# LPC865 register map
Vendor: nxp.com; File version: 1.0
CPU: CM0PLUS r0p0, little endian, no MPU, no FPU, VTOR, 2 interrupt priority bits
Registers are 32-bit, read-write, reset 0x0 unless marked. A register's access mark holds for its fields unless they carry their own. Offsets are from the block's base; [hi:lo] are bit positions; {n}, {i} and the like mark numbered series.

## I3C0 — I3C
Base 0x40060000
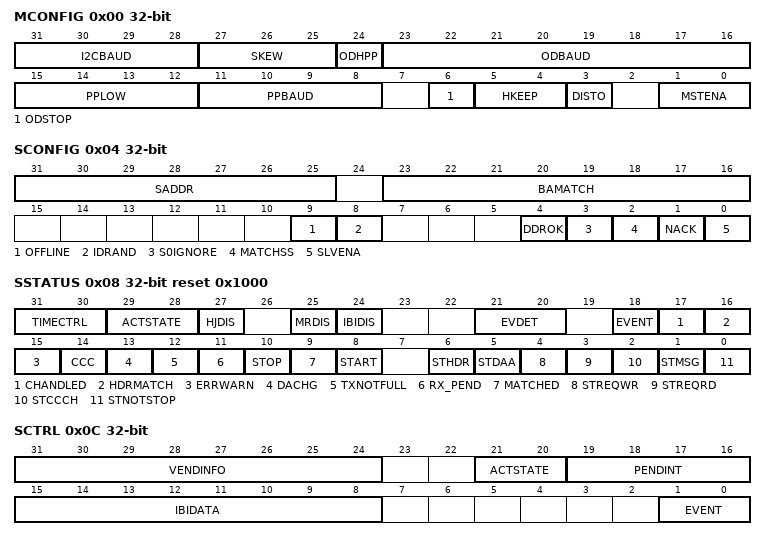
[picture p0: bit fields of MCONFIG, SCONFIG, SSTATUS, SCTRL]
0x00 MCONFIG — Master Configuration Register
  [31:28] I2CBAUD — I2C baud rate
  [27:25] SKEW
  [24] ODHPP — Open drain high push-pull
  [23:16] ODBAUD — Open drain baud rate
  [15:12] PPLOW — Push-Pull low
  [11:8] PPBAUD — Push-pull baud rate
  [6] ODSTOP — Open drain stop
  [5:4] HKEEP — High-Keeper
    0=NONE (NONE: Use PUR (Pull-Up Resistor). Hold SCL High.); 1=WIRED_IN (WIRED_IN: Wired-in High Keeper controls; use pin_HK (High Keeper) controls.); 2=PASSIVE_SDA (PASSIVE_SDA: Passive on SDA; can Hi-Z (high impedance) for Bus Free (IDLE) and hold.); 3=PASSIVE_ON_SDA_SCL (PASSIVE_ON_SDA_SCL: Passive on SDA and SCL; can Hi-Z (high impedance) both for Bus Free (IDLE), and can Hi-Z SDA for hold.)
  [3] DISTO — Disable Timeout
  [1:0] MSTENA — Master enable
    0=MASTER_OFF (MASTER_OFF: Master is off (is not enabled). If MASTER_OFF is enabled, then the I3C module can only use slave mode.); 1=MASTER_ON (MASTER_ON: Master is on (is enabled). When used from start-up, this I3C module is master by default (the main master). The module will control the bus unless the master is handed off. If the master is handed off, then MSTENA must move to 2 after that happens. The handoff means emitting GETACCMST and if accepted, the module will emit a STOP and set the MSTENA bit to 2 (or 0).); 2=MASTER_CAPABLE (MASTER_CAPABLE: The I3C module is master-capable; however the module is operating as a slave now. When used from the start, the I3C module will start as a slave, but will be prepared to switch to master mode. To switch to master mode, the slave emits an Master Request (MR), or gets a GETACCMST CCC command and accepts it (to switch on the STOP).)
0x04 SCONFIG — Slave Configuration Register
  [31:25] SADDR — Static address
  [23:16] BAMATCH — Bus available match
  [9] OFFLINE
  [8] IDRAND — ID random
  [4] DDROK — Double Data Rate OK
  [3] S0IGNORE — S0/S1 errors ignore
  [2] MATCHSS — Match START or STOP
  [1] NACK — Not acknowledge
  [0] SLVENA — Slave enable
0x08 SSTATUS reset 0x1000 (reset mask 0xFBC7FF7F) — Slave Status Register
  [31:30] TIMECTRL ro — Time control
    0=NO_TIME_CONTROL (NO_TIME_CONTROL: No time control is enabled); 2=ASYNC_MODE (ASYNC_MODE: Asynchronous standard mode (0) is enabled)
  [29:28] ACTSTATE ro — Activity state from Common Command Codes (CCC)
    0=NO_LATENCY (NO_LATENCY: normal bus operations); 1=LATENCY_1MS (LATENCY_1MS: 1 ms of latency); 2=LATENCY_100MS (LATENCY_100MS: 100 ms of latency); 3=LATENCY_10S (LATENCY_10S: 10 seconds of latency)
  [27] HJDIS ro — Hot-Join is disabled
  [25] MRDIS ro — Master requests are disabled
  [24] IBIDIS ro — In-Band Interrupts are disabled
  [21:20] EVDET ro — Event details
    0=NONE (NONE: no event or no pending event); 1=NO_REQUEST (NO_REQUEST: Request not sent yet. Either there was no START yet, or is waiting for Bus-Available or Bus-Idle (HJ).); 2=NACKED (NACKED: Not acknowledged(Request sent and NACKed); the module will try again.); 3=ACKED (ACKED: Acknowledged (Request sent and ACKed), so Done (unless the time control data is still being sent).)
  [18] EVENT
  [17] CHANDLED — Common-Command-Code handled
  [16] HDRMATCH — High Data Rate command match
  [15] ERRWARN ro — Error warning
  [14] CCC — Common Command Code
  [13] DACHG
  [12] TXNOTFULL ro — Transmit buffer is not full
  [11] RX_PEND ro — Received message pending
  [10] STOP
  [9] MATCHED
  [8] START
  [6] STHDR ro — Status High Data Rate
  [5] STDAA ro — Status Dynamic Address Assignment
  [4] STREQWR ro — Status request write
  [3] STREQRD ro — Status required
  [2] STCCCH ro — Status Common Command Code Handler
  [1] STMSG ro — Status message
  [0] STNOTSTOP ro — Status not stop
0x0C SCTRL — Slave Control Register
  [31:24] VENDINFO — Vendor information
  [21:20] ACTSTATE — Activity state (of slave)
  [19:16] PENDINT — Pending interrupt
  [15:8] IBIDATA — In-Band Interrupt data
  [1:0] EVENT
    0=NORMAL_MODE (NORMAL_MODE: If EVENT is set to 0 after was a non-0 value, event processing will cancel if the event processing has not yet started; if event processing has already been started, then event processing will not be be cancelled.); 1=IBI (IBI: Start an In-Band Interrupt. This will try to push an IBI interrupt onto the I3C bus. If data is associated with the IBI, then the data will be read from the SCTRL.IBIDATA field. If time control is enabled, then this data will also include any time control-related bytes; additionally, the IBIDATA byte will have bit 7 set to 1 automatically (as is required for time control). The IBI interrupt will occur after the 1st (mandatory) IBIDATA, if any.); 2=MASTER_REQUEST (MASTER_REQUEST: Start a Master-Request.); 3=HOT_JOIN_REQUEST (HOT_JOIN_REQUEST: Start a Hot-Join request. A Hot-Join Request should only be used when the device is powered on after the I3C bus is already powered up, or when the device is connected using hot insertion methods (the device is powered up when it is physically inserted onto the powered-up I3C bus). The hot join will wait for Bus Idle, and SCTRL.EVENT=HOT_JOIN_REQUEST must be set before the slave enable (SCONFIG.SLVENA).)
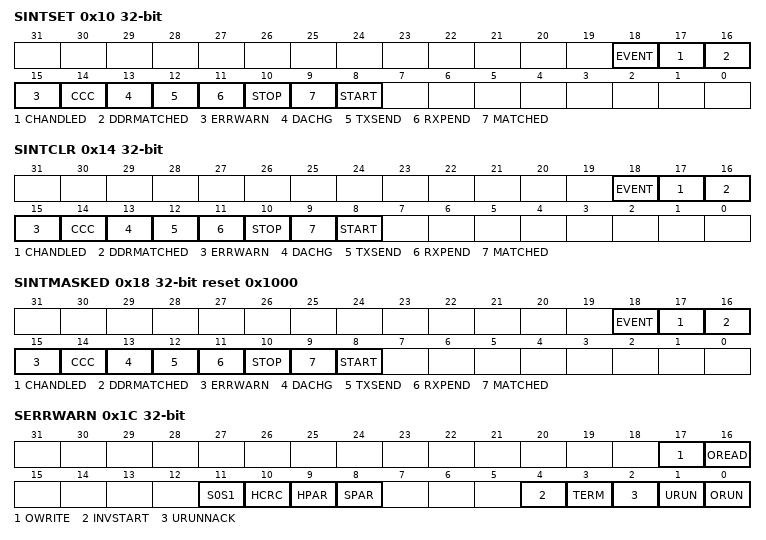
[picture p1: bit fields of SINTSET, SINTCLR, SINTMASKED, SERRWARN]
0x10 SINTSET — Slave Interrupt Set Register
  [18] EVENT — Event interrupt enable
  [17] CHANDLED — Common Command Code (CCC) (that was handled by I3C module) interrupt enable
  [16] DDRMATCHED — Double Data Rate (DDR) interrupt enable
  [15] ERRWARN — Error/warning interrupt enable
  [14] CCC — Common Command Code (CCC) (that was not handled by I3C module) interrupt enable
  [13] DACHG — Dynamic address change interrupt enable
  [12] TXSEND — Transmit interrupt enable
  [11] RXPEND — Receive interrupt enable
  [10] STOP — Stop interrupt enable
  [9] MATCHED — Match interrupt enable
  [8] START — Start interrupt enable
0x14 SINTCLR reset not defined write-1-clears — Slave Interrupt Clear Register
  [18] EVENT write-1-clears — EVENT interrupt enable clear
  [17] CHANDLED write-1-clears — CHANDLED interrupt enable clear
  [16] DDRMATCHED write-1-clears — DDRMATCHED interrupt enable clear
  [15] ERRWARN write-1-clears — ERRWARN interrupt enable clear
  [14] CCC write-1-clears — CCC interrupt enable clear
  [13] DACHG write-1-clears — DACHG interrupt enable clear
  [12] TXSEND write-1-clears — TXSEND interrupt enable clear
  [11] RXPEND write-1-clears — RXPEND interrupt enable clear
  [10] STOP write-1-clears — STOP interrupt enable clear
  [9] MATCHED write-1-clears — MATCHED interrupt enable clear
  [8] START write-1-clears — START interrupt enable clear
0x18 SINTMASKED ro reset 0x1000 — Slave Interrupt Mask Register
  [18] EVENT — EVENT interrupt mask
  [17] CHANDLED — CHANDLED interrupt mask
  [16] DDRMATCHED — DDRMATCHED interrupt mask
  [15] ERRWARN — ERRWARN interrupt mask
  [14] CCC — CCC interrupt mask
  [13] DACHG — DACHG interrupt mask
  [12] TXSEND — TXSEND interrupt mask
  [11] RXPEND — RXPEND interrupt mask
  [10] STOP — STOP interrupt mask
  [9] MATCHED — MATCHED interrupt mask
  [8] START — START interrupt mask
0x1C SERRWARN — Slave Errors and Warnings Register
  [17] OWRITE — Over-write error
  [16] OREAD — Over-read error
  [11] S0S1 — S0 or S1 error
  [10] HCRC — HDR-DDR CRC error
  [9] HPAR — HDR parity error
  [8] SPAR — SDR parity error
  [4] INVSTART — Invalid start error
  [3] TERM — Terminated error
  [2] URUNNACK — Underrun and Not Acknowledged (NACKed) error
  [1] URUN — Underrun error
  [0] ORUN — Overrun error
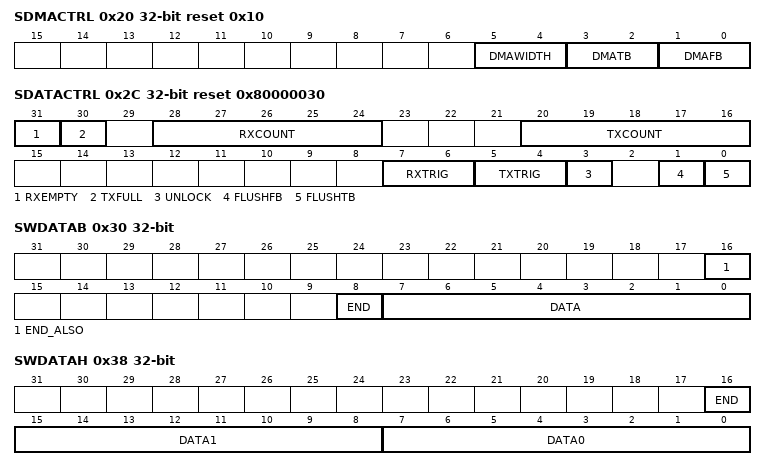
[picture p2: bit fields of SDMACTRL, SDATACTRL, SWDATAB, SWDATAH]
0x20 SDMACTRL reset 0x10 — Slave DMA Control Register
  [5:4] DMAWIDTH — Width of DMA operations
    0=BYTE; 1=BYTE_AGAIN; 2=HALF_WORD (HALF_WORD: Half word (16 bits). This will make sure that 2 bytes are free/available in the FIFO.)
  [3:2] DMATB — DMA Write (To-bus) trigger
    0=NOT_USED (NOT_USED: DMA is not used); 1=ENABLE_ONE_FRAME (ENABLE_ONE_FRAME: DMA is enabled for 1 Frame (ended by DMA or terminated). DMATB auto-clears on a STOP or START (see the Match START or STOP bit (SCONFIG.MATCHSS).); 2=ENABLE (ENABLE: DMA is enabled until turned off. Normally, ENABLE should only be used with Master Message mode.)
  [1:0] DMAFB — DMA Read (From-bus) trigger
    0=NOT_USED (DMA not used); 1=ENABLE_ONE_FRAME (DMA is enabled for 1 frame); 2=ENABLE (DMA enable)
0x2C SDATACTRL reset 0x80000030 (reset mask 0xDF1F00F7) — Slave Data Control Register
  [31] RXEMPTY ro — RX is empty
    0=RXISNOTEMPTY; 1=RXISEMPTY
  [30] TXFULL ro — TX is full
    0=TXISNOTFULL; 1=TXISFULL
  [28:24] RXCOUNT ro — Count of bytes in RX
  [20:16] TXCOUNT ro — Count of bytes in TX
  [7:6] RXTRIG — Trigger level for RX FIFO fullness
    0=TRIGGRNOTEMPTY (Trigger on not empty); 1=TRIGGRONEFOURTH (Trigger on or more full); 2=TRIGGRONEHALF (Trigger on .5 or more full); 3=TRIGGRTHREEFOURTHS (Trigger on 3/4 or more full)
  [5:4] TXTRIG — Trigger level for TX FIFO emptiness
    0=TRIGGREMPTY (Trigger on empty); 1=TRIGGRONEFOURTH (Trigger on full or less); 2=TRIGGRONEHALF (Trigger on .5 full or less); 3=TRIGGRONELESS (Trigger on 1 less than full or less (Default))
  [3] UNLOCK wo
  [1] FLUSHFB wo — Flushes the from-bus buffer/FIFO
  [0] FLUSHTB wo — Flush the to-bus buffer/FIFO
0x30 SWDATAB wo reset not defined — Slave Write Data Byte Register
  [16] END_ALSO
  [8] END
  [7:0] DATA — The data byte to send to the master
0x34 SWDATABE wo reset not defined — Slave Write Data Byte End
  [7:0] DATA — The data byte to send to the master
0x38 SWDATAH wo reset not defined — Slave Write Data Half-word Register
  [16] END — End of message
  [15:8] DATA1 — The 2nd byte to send to the master
  [7:0] DATA0 — The 1st byte to send to the master
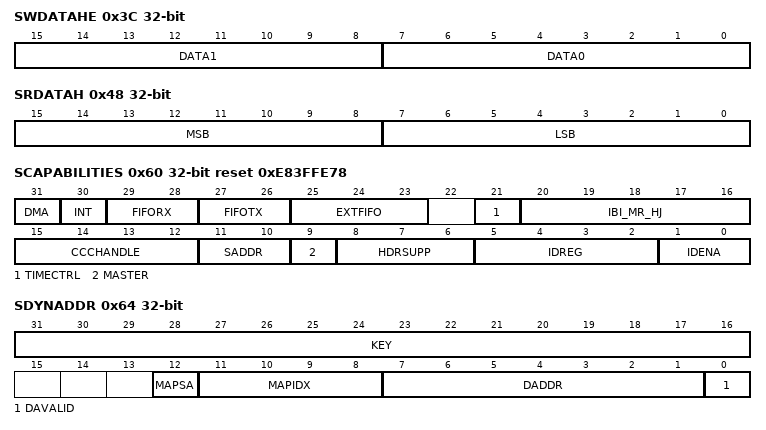
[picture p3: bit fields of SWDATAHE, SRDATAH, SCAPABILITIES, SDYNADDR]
0x3C SWDATAHE wo reset not defined — Slave Write Data Half-word End Register
  [15:8] DATA1 — The 2nd byte to send to the master
  [7:0] DATA0 — The 1st byte to send to the master
0x40 SRDATAB ro — Slave Read Data Byte Register
  [7:0] DATA0 — Byte read from the master
0x48 SRDATAH ro — Slave Read Data Half-word Register
  [15:8] MSB — The 2nd byte read from the slave
  [7:0] LSB — The 1st byte read from the slave
0x54 SWDATAB1 wo — Target Write Data Byte Register
  [7:0] DATA — The data byte rto send to controller
0x60 SCAPABILITIES ro reset 0xE83FFE78 — Slave Capabilities Register
  [31] DMA
    0=DMANO (DMA is not supported); 1=DMAYES (DMA is supported)
  [30] INT
    0=INTERRUPTSNO (Interrupts are not supported); 1=INTERRUPTSYES (Interrupts are supported)
  [29:28] FIFORX — FIFO receive
    0=FIFO_2BYTE (FIFO_2BYTE: 2 (or 3)-byte RX FIFO, the default FIFO receive value (FIFORX)); 1=FIFO_4BYTE (FIFO_4BYTE: 4-byte RX FIFO); 2=FIFO_8BYTE (FIFO_8BYTE: 8-byte RX FIFO); 3=FIFO_16BYTE (FIFO_16BYTE: 16-byte RX FIFO)
  [27:26] FIFOTX — FIFO transmit
    0=FIFO_2BYTE (FIFO_2BYTE: 2-byte TX FIFO, the default FIFO transmit value (FIFOTX)); 1=FIFO_4BYTE (FIFO_4BYTE: 4-byte TX FIFO); 2=FIFO_8BYTE (FIFO_8BYTE: 8-byte TX FIFO); 3=FIFO_16BYTE (FIFO_16BYTE: 16-byte TX FIFO)
  [25:23] EXTFIFO — External FIFO
    1=STD_EXT_FIFO (STD_EXT_FIFO: standard available/free external FIFO)
  [21] TIMECTRL — Time control
    0=NO_TIME_CONTROL_TYPE (NO_TIME_CONTROL_TYPE: No time control is enabled); 1=ATLEAST1_TIME_CONTROL (ATLEAST1_TIME_CONTROL: at least one time-control type is supported)
  [20:16] IBI_MR_HJ — In-Band Interrupts, Master Requests, Hot Join events
  [15:12] CCCHANDLE — Common Command Codes (CCC) handling
  [11:10] SADDR — Static address
    0=NO_STATIC (NO_STATIC: No static address); 1=STATIC (STATIC: Static address is fixed in hardware); 2=HW_CONTROL (HW_CONTROL: Hardware controls the static address dynamically (for example, from the pin strap)); 3=CONFIG (CONFIG: SCONFIG register supplies the static address)
  [9] MASTER
    0=MASTERNOTSUPPORTED (MASTERNOTSUPPORTED: master capability is not supported.); 1=MASTERSUPPORTED (MASTERSUPPORTED: master capability is supported.)
  [8:6] HDRSUPP — HDR support
  [5:2] IDREG — ID register
  [1:0] IDENA — ID 48b handler
    0=APPLICATION (APPLICATION: Application handles ID 48b); 1=HW (HW: Hardware handles ID 48b); 2=HW_BUT (HW_BUT: in hardware but the I3C module instance handles ID 48b.); 3=PARTNO (PARTNO: a part number register (PARTNO) handles ID 48b)
0x64 SDYNADDR (reset mask 0xFFFF00FF) — Slave Dynamic Address Register
  [31:16] KEY
  [12] MAPSA wo — Map a Static Address
  [11:8] MAPIDX wo — Mapped Dynamic Address
  [7:1] DADDR — Dynamic address
  [0] DAVALID
    0=DANOTASSIGNED (DANOTASSIGNED: a Dynamic Address is not assigned); 1=DAASSIGNED (DAASSIGNED: a Dynamic Address is assigned)
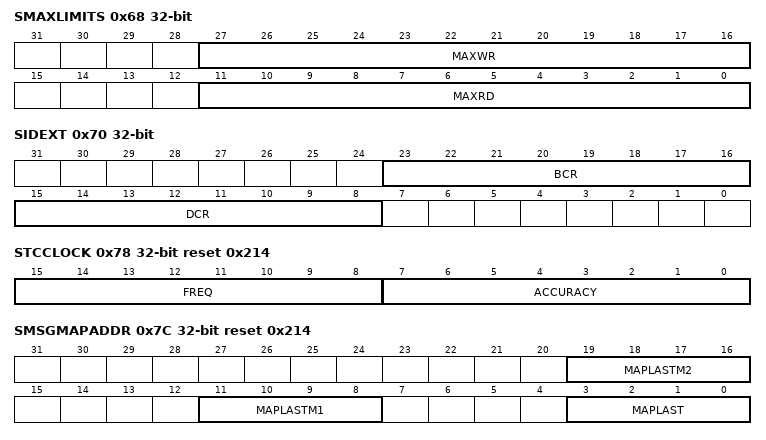
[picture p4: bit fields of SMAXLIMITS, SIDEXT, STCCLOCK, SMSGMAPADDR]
0x68 SMAXLIMITS (reset mask 0xFFF0FFF0) — Slave Maximum Limits Register
  [27:16] MAXWR — Maximum write length
  [11:0] MAXRD — Maximum read length
0x6C SIDPARTNO — Slave ID Part Number Register
  [31:0] PARTNO — Part number
0x70 SIDEXT — Slave ID Extension Register
  [23:16] BCR — Bus Characteristics Register
  [15:8] DCR — Device Characteristic Register
0x74 SVENDORID reset 0x11B — Slave Vendor ID Register
  [14:0] VID — Vendor ID
0x78 STCCLOCK reset 0x214 — Slave Time Control Clock Register
  [15:8] FREQ — Clock frequency
  [7:0] ACCURACY — Clock accuracy
0x7C SMSGMAPADDR ro reset 0x214 (reset mask 0xFFFF) — Slave Message-Mapped Address Register
  [19:16] MAPLASTM2 — Previous match index 2
  [11:8] MAPLASTM1 — Previous match index 1
  [3:0] MAPLAST — Matched address index
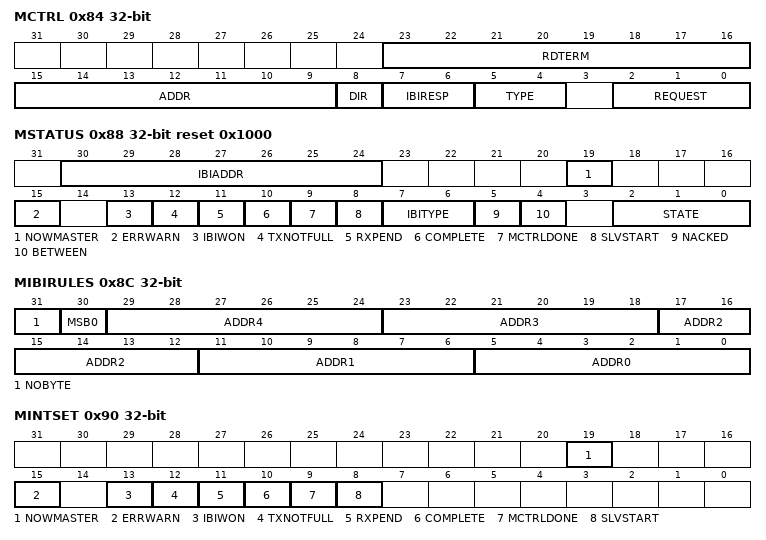
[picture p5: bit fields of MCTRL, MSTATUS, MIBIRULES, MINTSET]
0x84 MCTRL — Master Main Control Register
  [23:16] RDTERM — Read terminate
  [15:9] ADDR
  [8] DIR
    0=DIRWRITE (DIRWRITE: Write); 1=DIRREAD (DIRREAD: Read)
  [7:6] IBIRESP — In-Band Interrupt (IBI) response
    0=ACK (ACK: Acknowledge. A mandatory byte (or not) is decided by the Master In-band Interrupt Registry and Rules Register (MIBIRULES). To limit the maximum number of IBI bytes, configure the Read Termination field (MCTRL.RDTERM).); 1=NACK (NACK: Not acknowledge); 2=ACK_WITH_MANDATORY (ACK_WITH_MANDATORY: Acknowledge with mandatory byte (ignores the MIBIRULES register). Acknowledge with mandatory byte should not be used, unless only slaves with a mandatory byte can cause an In-Band Interrupt.); 3=MANUAL (MANUAL: stop and wait for a decision using the IBIAckNack request)
  [5:4] TYPE — Bus type with START
    0=I3C (I3C: Normally the SDR mode of I3C. For ForceExit, the Exit pattern.); 1=I2C (I2C: Normally the Standard I2C protocol.); 2=DDR (DDR: (Double Data Rate): Normally the HDR-DDR mode of I3C. Enter DDR mode (7E and then ENTHDR0), if the module is not already in DDR mode. The 1st byte written to the TX FIFO should be a command, and should already be in the FIFO. To end DDR mode, use ForceExit. For ForceExit, the normal IBHR (In-Band Hardware Reset).); 3=FORCEDIBHR (For ForcedExit, this is forced IBHR.)
  [2:0] REQUEST
    0=NONE (NONE: Returns to this when finished with any request. The MSTATUS register indicates the master's state. See also AutoIBI mode. NONE is only written as 0: when setting RDTERM to 1 (to stop a read in progress) or when setting IBI reponse field (IBIRESP) for MSG use); 1=EMITSTARTADDR (EMITSTARTADDR: Emit START with address and direction from a stopped state or in the middle of a Single Data Rate (SDR) message. If from a stopped state (IDLE), then emit start may be prevented by an event (like IBI, MR, HJ), in which case the appropriate interrupt is signaled; note that Emit START can be resubmitted.); 2=EMITSTOP (EMITSTOP: Emit a STOP on bus. Must be in Single Data Rate (SDR) mode. If in Dynamic Address Assignment (DAA) mode, Emit stop will exit DAA mode.); 3=IBIACKNACK (IBIACKNACK: Manual In-Band Interrupt (IBI) Acknowledge (ACK) or Not Acknowledge (NACK). When IBIRESP has indicated a hold on an In-Band Interrupt to allow a manual decision, this request completes it. Uses IBIRESP to provide the information.); 4=PROCESSDAA (PROCESSDAA: If not in Dynamic Address Assignment (DAA) mode now, will issue START, 7E, ENTDAA, and then will emit 7E/R to process each slave. Will stop just before the new Dynamic Address (DA) is to be emitted. The next Process DAA request will use the Addr field as the new DA to assign. If NACKed on the 7E/R, then the interrupt will indicate this situation, and a STOP will be emitted.); 6=FORCEEXIT (FORCEEXIT and IBHR: Emit an Exit Pattern from any state, but end Double Data Rate (DDR) (including MSGDDR), if in DDR mode now. Includes a STOP afterward. If TYPE != 0, then it will perform an IBHR (In-Band Hardware Reset). If TYPE=2, then it does a normal reset (DEFRST can prevent the reset). If TYPE=3, it does a forced reset (will always reset).); 7=AUTOIBI (AUTOIBI: Hold in a stopped state, but auto-emit START,7E when the slave is holding down SDA to get an In-Band Interrupt (IBI). Actual In-Band Interrupt handling is defined by IBIRESP.)
0x88 MSTATUS reset 0x1000 — Master Status Register
  [30:24] IBIADDR ro — IBI address
  [19] NOWMASTER — Now master (now this module is a master)
  [15] ERRWARN ro — Error or warning
  [13] IBIWON — In-Band Interrupt (IBI) won
  [12] TXNOTFULL ro — TX buffer/FIFO not yet full
  [11] RXPEND ro
  [10] COMPLETE
  [9] MCTRLDONE — Master control done
  [8] SLVSTART — Slave start
  [7:6] IBITYPE ro — In-Band Interrupt (IBI) type
    0=NONE (NONE: cleared when IBI Won bit (MSTATUS.IBIWON) is cleared); 1=IBI (IBI: In-Band Interrupt); 2=MR (MR: Master Request); 3=HJ (HJ: Hot-Join)
  [5] NACKED ro — Not acknowledged
  [4] BETWEEN ro — Between messages or Dynamic Address Assignments (DAA)
  [2:0] STATE ro — State of the master
    0=IDLE (IDLE: the bus has STOPped.); 1=SLVREQ (SLVREQ: (Slave Request state) the bus has STOPped but a slave is holding SDA low. If using auto-emit IBI (MCTRL.AutoIBI), then the master will not stay in the Slave Request state.); 2=MSGSDR (MSGSDR: in Single Data Rate (SDR) Message state (from using MWMSG_SDR)); 3=NORMACT (NORMACT: normal active Single Data Rate (SDR) state (from using MCTRL and MWDATAn and MRDATAn registers). The master will stay in the NORMACT state until a STOP is issued.); 4=DDR (MSGDDR: in Double Data Rate (DDR) Message mode (from using MWMSG_DDR or using the normal method with DDR). The master will stay in the DDR state, until the master exits using EXIT (emits the Exit pattern).); 5=DAA (DAA: in Enter Dynamic Address Assignment (ENTDAA) mode); 6=IBIACK (IBIACK: waiting for an In-Band Interrupt (IBI) ACK/NACK decision); 7=IBIRCV (IBIRCV: Receiving an In-Band Interrupt (IBI); this IBIRCV state is used after IBI/MR/HJ has won the arbitration, and IBIRCV state is also used for IBI mandatory byte (if any) and any bytes that follow.)
0x8C MIBIRULES — Master In-band Interrupt Registry and Rules Register
  [31] NOBYTE — No IBI byte
  [30] MSB0 — Set Most Significant address Bit to 0
  [6n+5:6n] ADDR{n} (n=0..4)
0x90 MINTSET — Master Interrupt Set Register
  [19] NOWMASTER — Now master (now this I3C module is a master) interrupt enable
  [15] ERRWARN — Error or warning (ERRWARN) interrupt enable
  [13] IBIWON — In-Band Interrupt (IBI) won interrupt enable
  [12] TXNOTFULL — TX buffer/FIFO is not full interrupt enable
  [11] RXPEND — RX pending interrupt enable
  [10] COMPLETE — Completed message interrupt enable
  [9] MCTRLDONE — Master control done interrupt enable
  [8] SLVSTART — Slave start interrupt enable
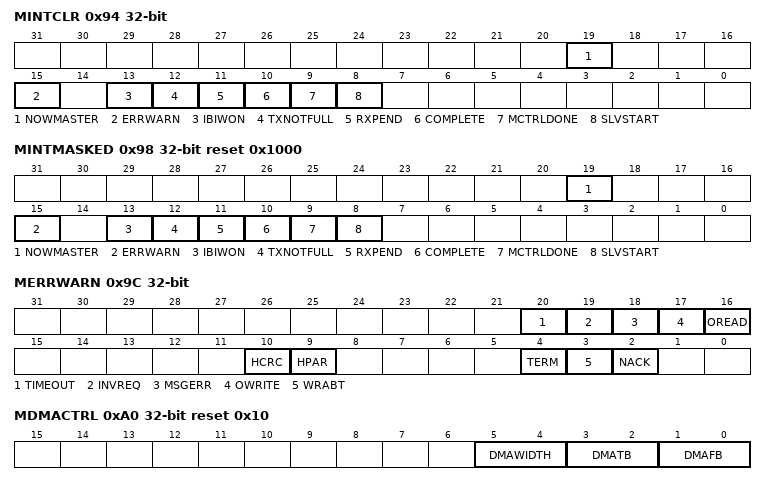
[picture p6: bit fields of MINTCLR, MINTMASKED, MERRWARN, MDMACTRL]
0x94 MINTCLR wo reset not defined — Master Interrupt Clear Register
  [19] NOWMASTER — NOWMASTER interrupt enable clear
  [15] ERRWARN — ERRWARN interrupt enable clear
  [13] IBIWON — IBIWON interrupt enable clear
  [12] TXNOTFULL — TXNOTFULL interrupt enable clear
  [11] RXPEND — RXPEND interrupt enable clear
  [10] COMPLETE — COMPLETE interrupt enable clear
  [9] MCTRLDONE — MCTRLDONE interrupt enable clear
  [8] SLVSTART — SLVSTART interrupt enable clear
0x98 MINTMASKED ro reset 0x1000 — Master Interrupt Mask Register
  [19] NOWMASTER — NOWMASTER interrupt mask
  [15] ERRWARN — ERRWARN interrupt mask
  [13] IBIWON — IBIWON interrupt mask
  [12] TXNOTFULL — TXNOTFULL interrupt mask
  [11] RXPEND — RXPEND interrupt mask
  [10] COMPLETE — COMPLETE interrupt mask
  [9] MCTRLDONE — MCTRLDONE interrupt mask
  [8] SLVSTART — SLVSTART interrupt mask
0x9C MERRWARN — Master Errors and Warnings Register
  [20] TIMEOUT — TIMEOUT error
  [19] INVREQ — Invalid request error
  [18] MSGERR — Message error
  [17] OWRITE — Over-write error
  [16] OREAD — Over-read error
  [10] HCRC — High data rate CRC error
  [9] HPAR — High data rate parity
  [4] TERM — Terminate error
  [3] WRABT — WRABT (Write abort) error
  [2] NACK — Not acknowledge (NACK) error
0xA0 MDMACTRL reset 0x10 — Master DMA Control Register
  [5:4] DMAWIDTH
    0=BYTE; 1=BYTE_AGAIN; 2=HALF_WORD (HALF_WORD: Half-word (16 bits). This will make sure that 2 bytes are free/available in FIFO.)
  [3:2] DMATB — DMA to bus
    0=NOT_USED (NOT_USED: DMA is not used); 1=ENABLE_ONE_FRAME (ENABLE_ONE_FRAME: DMA is enabled for 1 frame (ended by DMA or Terminated). DMATB auto-clears on STOP or START. See MCONFIG.MATCHSS.); 2=ENABLE (ENABLE: DMA is enabled until DMA is turned off. Normally DMA ENABLE should only be used in Master Message mode.)
  [1:0] DMAFB — DMA from bus
    0=NOT_USED (NOT_USED: DMA is not used); 1=ENABLE_ONE_FRAME (ENABLE_ONE_FRAME: DMA is enabled for 1 frame. DMAFB auto-clears on STOP or repeated START. See MCONFIG.MATCHSS.); 2=ENABLE (ENABLE: DMA is enabled until the DMA is turned off.)
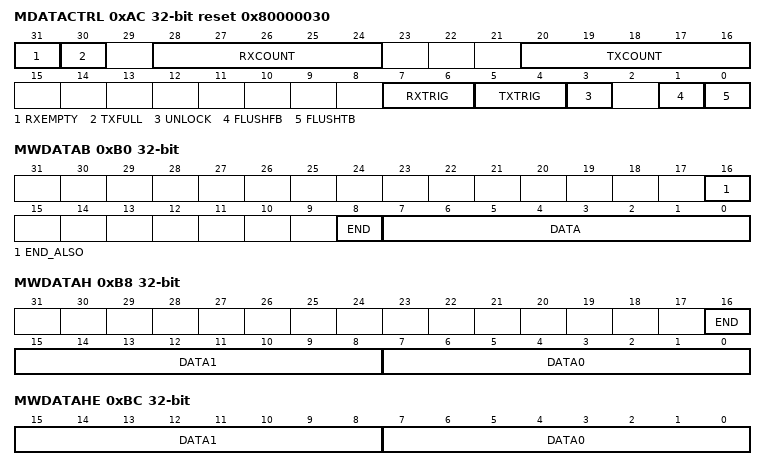
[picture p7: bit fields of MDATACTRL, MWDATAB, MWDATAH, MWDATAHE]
0xAC MDATACTRL reset 0x80000030 (reset mask 0xDF1F00F7) — Master Data Control Register
  [31] RXEMPTY ro — RX is empty
  [30] TXFULL ro — TX is full
  [28:24] RXCOUNT ro — RX byte count
  [20:16] TXCOUNT ro — TX byte count
  [7:6] RXTRIG — RX trigger level
  [5:4] TXTRIG — TX trigger level
  [3] UNLOCK wo
  [1] FLUSHFB wo — Flush from-bus buffer/FIFO
  [0] FLUSHTB wo — Flush to-bus buffer/FIFO
0xB0 MWDATAB wo reset not defined — Master Write Data Byte Register
  [16] END_ALSO — End of message also
  [8] END — End of message
  [7:0] DATA — Data byte
0xB4 MWDATABE wo reset not defined — Master Write Data Byte End Register
  [7:0] DATA
0xB8 MWDATAH wo reset not defined — Master Write Data Half-word Register
  [16] END — End of message
  [15:8] DATA1 — Data byte 1
  [7:0] DATA0 — Data byte 0
0xBC MWDATAHE wo reset not defined — Master Write Data Byte End Register
  [15:8] DATA1, [7:0] DATA0
0xC0 MRDATAB ro — Master Read Data Byte Register
  [7:0] VALUE
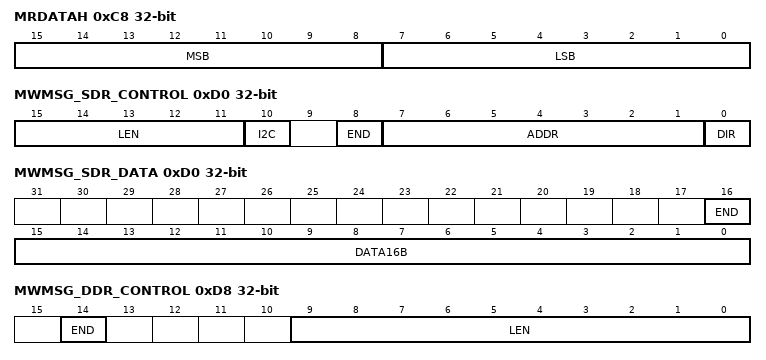
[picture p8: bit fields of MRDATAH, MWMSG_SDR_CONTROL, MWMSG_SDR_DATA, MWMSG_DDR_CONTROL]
0xC8 MRDATAH ro — Master Read Data Half-word Register
  [15:8] MSB, [7:0] LSB
0xCC MWDATAB1 ro — Controller Write Byte Data 1
  [7:0] VALUE
0xD0 MWMSG_SDR_CONTROL wo reset not defined (MWMSG_SDR view) — Master Write Message in SDR mode
  [15:11] LEN — Length
  [10] I2C
    0=I3CMESSAGE; 1=I2CMESSAGE
  [8] END — End of SDR message
  [7:1] ADDR — Address to be written to
  [0] DIR — Direction
    0=WRITE; 1=READ
0xD0 MWMSG_SDR_DATA wo (MWMSG_SDR view) — Master Write Message Data in SDR mode
  [16] END — End of message
  [15:0] DATA16B — Data
0xD4 MRMSG_SDR ro — Master Read Message in SDR mode
  [15:0] DATA
0xD8 MWMSG_DDR_CONTROL wo reset not defined (MWMSG_DDR view) — Master Write Message in DDR mode
  [14] END — End of message
  [9:0] LEN — Length of message
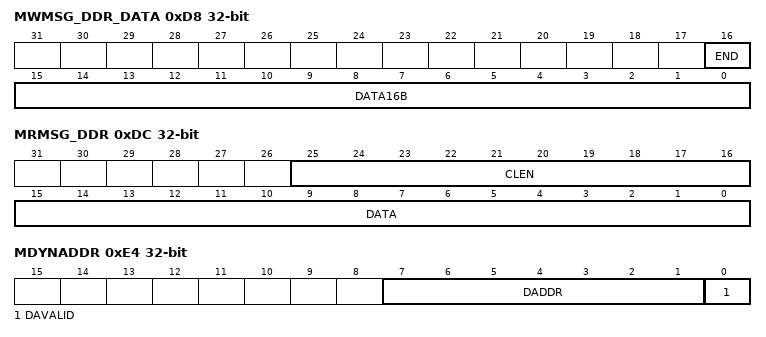
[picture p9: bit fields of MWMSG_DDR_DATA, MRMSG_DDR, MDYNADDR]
0xD8 MWMSG_DDR_DATA wo (MWMSG_DDR view) — Master Write Message Data in DDR mode
  [16] END — End of message
  [15:0] DATA16B — Data
0xDC MRMSG_DDR — Master Read Message in DDR mode
  [25:16] CLEN — Current length
  [15:0] DATA
0xE4 MDYNADDR — Master Dynamic Address Register
  [7:1] DADDR — Dynamic address
  [0] DAVALID — Dynamic address valid
0xFFC SID ro reset 0xEDCB0000 — Slave Module ID Register
  [31:0] ID
